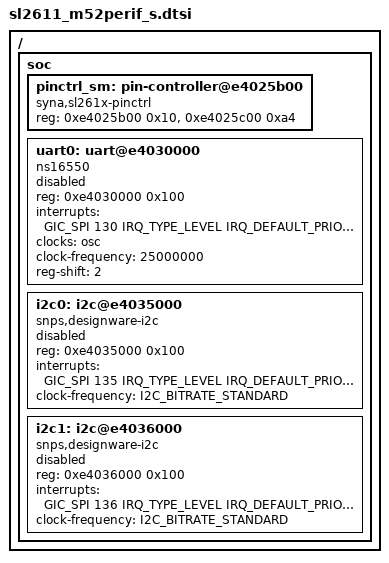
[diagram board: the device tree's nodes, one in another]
/*
 * Copyright (c) 2026 Synaptics Incorporated
 * Author: Jisheng Zhang <jszhang@kernel.org>
 *
 * SPDX-License-Identifier: Apache-2.0
 */

#include <zephyr/dt-bindings/i2c/i2c.h>
#include <zephyr/dt-bindings/interrupt-controller/arm-gic.h>

/ {
	soc {
		pinctrl_sm: pin-controller@e4025b00 {
			compatible = "syna,sl261x-pinctrl";
			reg = <0xe4025b00 0x10>, <0xe4025c00 0xa4>;
			reg-names = "pinmux", "pincfg";
		};

		uart0: uart@e4030000 {
			compatible = "ns16550";
			reg = <0xe4030000 0x100>;
			interrupts = <GIC_SPI 130 IRQ_TYPE_LEVEL IRQ_DEFAULT_PRIORITY>;
			clocks = <&osc>;
			clock-frequency = <25000000>;
			reg-shift = <2>;
			status = "disabled";
		};

		i2c0: i2c@e4035000 {
			compatible = "snps,designware-i2c";
			reg = <0xe4035000 0x100>;
			#address-cells = <1>;
			#size-cells = <0>;
			interrupts = <GIC_SPI 135 IRQ_TYPE_LEVEL IRQ_DEFAULT_PRIORITY>;
			clock-frequency = <I2C_BITRATE_STANDARD>;
			status = "disabled";
		};

		i2c1: i2c@e4036000 {
			compatible = "snps,designware-i2c";
			reg = <0xe4036000 0x100>;
			#address-cells = <1>;
			#size-cells = <0>;
			interrupts = <GIC_SPI 136 IRQ_TYPE_LEVEL IRQ_DEFAULT_PRIORITY>;
			clock-frequency = <I2C_BITRATE_STANDARD>;
			status = "disabled";
		};
	};
};
